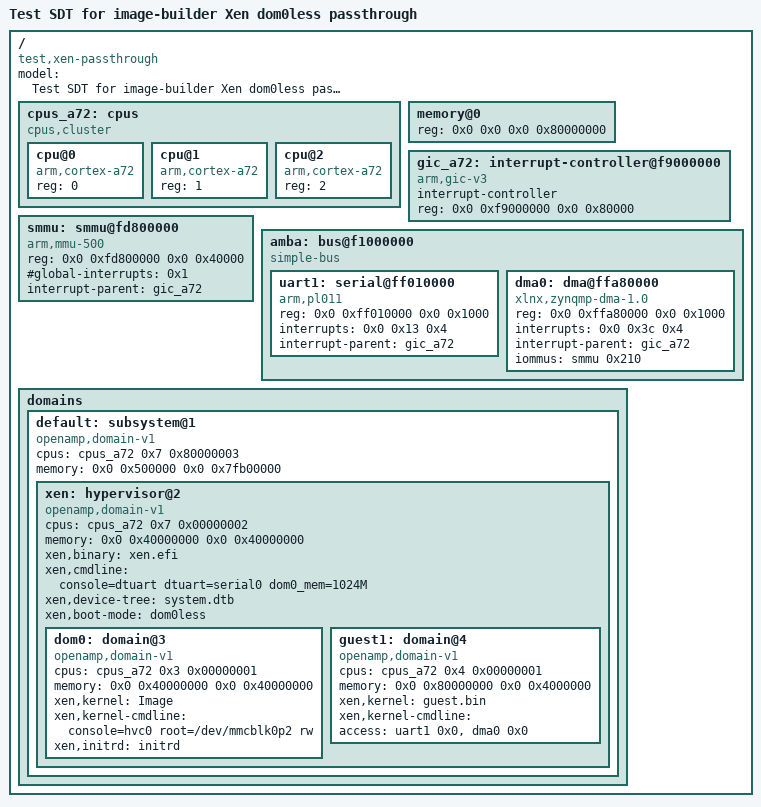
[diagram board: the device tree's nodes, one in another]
/dts-v1/;

/*
 * Test SDT fixture — dom0less Xen with device passthrough (SSW-9163).
 *
 * A hypervisor container + dom0 + one dom0less guest whose `access` list
 * points at two devices:
 *   - serial@ff010000 : no iommus -> xen,force-assign-without-iommu
 *   - dma@ffa80000    : iommus = <&smmu 0x210> -> xen,smmu-stream-ids
 *
 * Exercises single-pass passthrough fragment generation from image-builder
 * --gen-config, including SMMU stream-id extraction and the non-iommu
 * fallback.
 */

/ {
	compatible = "test,xen-passthrough";
	#address-cells = <2>;
	#size-cells = <2>;
	model = "Test SDT for image-builder Xen dom0less passthrough";

	cpus_a72: cpus {
		#address-cells = <1>;
		#size-cells = <0>;
		#cpus-mask-cells = <1>;
		compatible = "cpus,cluster";

		cpu@0 { compatible = "arm,cortex-a72"; device_type = "cpu"; reg = <0>; };
		cpu@1 { compatible = "arm,cortex-a72"; device_type = "cpu"; reg = <1>; };
		cpu@2 { compatible = "arm,cortex-a72"; device_type = "cpu"; reg = <2>; };
	};

	memory@0 {
		device_type = "memory";
		reg = <0x0 0x0 0x0 0x80000000>;
	};

	gic_a72: interrupt-controller@f9000000 {
		compatible = "arm,gic-v3";
		interrupt-controller;
		#interrupt-cells = <3>;
		reg = <0x0 0xf9000000 0x0 0x80000>;
	};

	smmu: smmu@fd800000 {
		compatible = "arm,mmu-500";
		status = "okay";
		reg = <0x0 0xfd800000 0x0 0x40000>;
		#iommu-cells = <0x1>;
		#global-interrupts = <0x1>;
		interrupt-parent = <&gic_a72>;
	};

	amba: bus@f1000000 {
		compatible = "simple-bus";
		#address-cells = <2>;
		#size-cells = <2>;
		ranges;

		uart1: serial@ff010000 {
			compatible = "arm,pl011", "arm,sbsa-uart";
			reg = <0x0 0xff010000 0x0 0x1000>;
			interrupts = <0x0 0x13 0x4>;
			interrupt-parent = <&gic_a72>;
			status = "okay";
		};

		dma0: dma@ffa80000 {
			compatible = "xlnx,zynqmp-dma-1.0";
			reg = <0x0 0xffa80000 0x0 0x1000>;
			interrupts = <0x0 0x3c 0x4>;
			interrupt-parent = <&gic_a72>;
			#stream-id-cells = <0x1>;
			iommus = <&smmu 0x210>;
			status = "okay";
		};
	};

	domains {
		#address-cells = <2>;
		#size-cells = <2>;

		default: subsystem@1 {
			compatible = "openamp,domain-v1";
			cpus = <&cpus_a72 0x7 0x80000003>;
			memory = <0x0 0x500000 0x0 0x7fb00000>;

			xen: hypervisor@2 {
				compatible = "openamp,domain-v1", "openamp,hypervisor-v1";
				cpus = <&cpus_a72 0x7 0x00000002>;
				memory = <0x0 0x40000000 0x0 0x40000000>;

				xen,binary = "xen.efi";
				xen,cmdline = "console=dtuart dtuart=serial0 dom0_mem=1024M";
				xen,device-tree = "system.dtb";
				xen,boot-mode = "dom0less";

				dom0: domain@3 {
					compatible = "openamp,domain-v1", "xen,domain-v2";
					cpus = <&cpus_a72 0x3 0x00000001>;
					memory = <0x0 0x40000000 0x0 0x40000000>;
					xen,kernel = "Image";
					xen,kernel-cmdline = "console=hvc0 root=/dev/mmcblk0p2 rw";
					xen,initrd = "initrd";
				};

				guest1: domain@4 {
					compatible = "openamp,domain-v1", "xen,domain-v2";
					cpus = <&cpus_a72 0x4 0x00000001>;
					memory = <0x0 0x80000000 0x0 0x4000000>;
					xen,kernel = "guest.bin";
					xen,kernel-cmdline = "";
					access = <&uart1 0x0 &dma0 0x0>;
				};
			};
		};
	};
};
